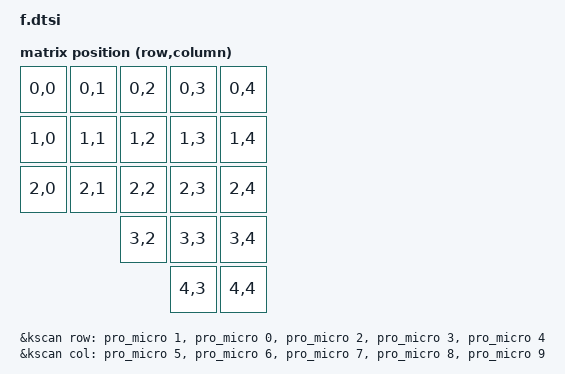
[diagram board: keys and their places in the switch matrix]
// This file was generated from a template. Edit it to match your keyboard.
// See https://zmk.dev/docs/development/hardware-integration/new-shield for more
// instructions.

#include <dt-bindings/zmk/matrix_transform.h>

#include "f-layouts.dtsi"

/ {
    chosen {
        zmk,physical-layout = &default_layout;
    };
&kscan {
    compatible = "zmk,kscan-gpio-matrix";
    diode-direction = "row2col";
    wakeup-source;

    // Columns get pull-downs for row2col
    col-gpios = <&pro_micro 5 (GPIO_ACTIVE_HIGH | GPIO_PULL_DOWN)>,
                <&pro_micro 6 (GPIO_ACTIVE_HIGH | GPIO_PULL_DOWN)>,
                <&pro_micro 7 (GPIO_ACTIVE_HIGH | GPIO_PULL_DOWN)>,
                <&pro_micro 8 (GPIO_ACTIVE_HIGH | GPIO_PULL_DOWN)>,
                <&pro_micro 9 (GPIO_ACTIVE_HIGH | GPIO_PULL_DOWN)>;

    // Rows have no pull
    row-gpios = <&pro_micro 1 GPIO_ACTIVE_HIGH>,
                <&pro_micro 0 GPIO_ACTIVE_HIGH>,
                <&pro_micro 2 GPIO_ACTIVE_HIGH>,
                <&pro_micro 3 GPIO_ACTIVE_HIGH>,
                <&pro_micro 4 GPIO_ACTIVE_HIGH>;
};
    default_transform: default_transform {
        // See https://zmk.dev/docs/development/hardware-integration/new-shield#matrix-transform
        // for how to configure this
        compatible = "zmk,matrix-transform";
        columns = <5>;
        rows = <5>;

        map = <
            RC(0, 0) RC(0, 1) RC(0, 2) RC(0, 3) RC(0, 4)
            RC(1, 0) RC(1, 1) RC(1, 2) RC(1, 3) RC(1, 4)
            RC(2, 0) RC(2, 1) RC(2, 2) RC(2, 3) RC(2, 4)
                              RC(3, 2) RC(3, 3) RC(3, 4)
                                       RC(4, 3) RC(4, 4)
        >;
    };
};
